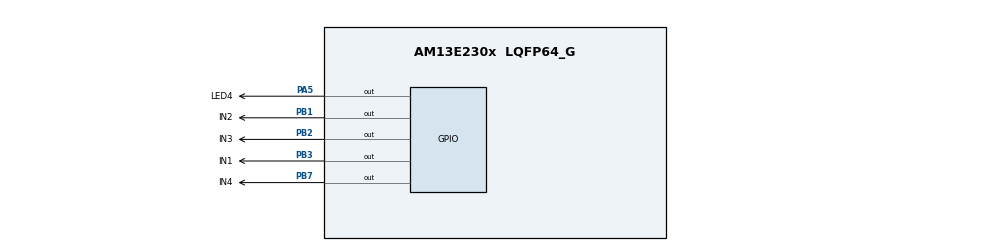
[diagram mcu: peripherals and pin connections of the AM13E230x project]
/**
 * @cliArgs --device "AM13E230x" --part "AM13E230x" --package "LQFP64_G" --product "AM13E2X SDK@26.01.00"
 */
// Kit 28BYJ-48 stepper on its ULN2003 driver board: four plain outputs, all on port B so one write moves them together.
// IN1 PB3 (J4 pin 40), IN2 PB1 (J4 pin 38), IN3 PB2 (J4 pin 36), IN4 PB7 (J4 pin 34). LED4 (PA5, low = on) while stepping.
const gpio   = scripting.addModule("/drivers/gpio", {}, false);
const gpio1  = gpio.addInstance();
const gpio2  = gpio.addInstance();
const sysctl = scripting.addModule("/drivers/sysctl");

gpio1.$name                          = "GPIO_LED";
gpio1.associatedPins[0].$name        = "LED4";
gpio1.associatedPins[0].initialValue = "SET";
gpio1.associatedPins[0].pin.$assign  = "PA5";

gpio2.$name                          = "STEP";
gpio2.associatedPins.create(4);
gpio2.associatedPins[0].$name        = "IN1";
gpio2.associatedPins[0].pin.$assign  = "PB3";
gpio2.associatedPins[1].$name        = "IN2";
gpio2.associatedPins[1].pin.$assign  = "PB1";
gpio2.associatedPins[2].$name        = "IN3";
gpio2.associatedPins[2].pin.$assign  = "PB2";
gpio2.associatedPins[3].$name        = "IN4";
gpio2.associatedPins[3].pin.$assign  = "PB7";

sysctl.VREFSource         = "DL_SYSCTL_VREF_INTERNAL_3_3_V";
sysctl.peripheral.$assign = "SYSCTL";
sysctl.useHFCLK     = true;
sysctl.SYSPLLSource = "DL_SYSCTL_SYSPLL_REF_HFCLK";
sysctl.SYSPLL_Qdiv  = 32;
sysctl.peripheral.x1Pin.$suggestSolution = "PC16_X1";
sysctl.peripheral.x2Pin.$suggestSolution = "PC17_X2";
